AUTOSAR XML (schema 00046)
package /ComponentTypes
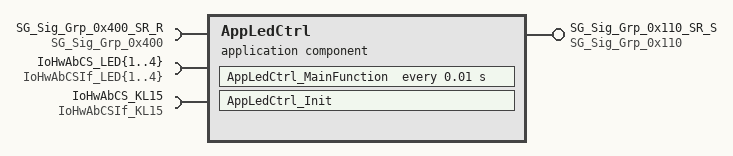
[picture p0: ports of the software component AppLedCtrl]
  application sw component type AppLedCtrl
    require port SG_Sig_Grp_0x400_SR_R: nonqueued-receiver-com-spec{data-element=SG_Sig_Grp_0x400, filter=data-filter-type=ALWAYS, init-value=fields=[CrcSig_Pack_0:0, CrcSig_Pack_1:0, CrcSig_Pack_2:0, Led1_Control:1, Led2_Control:1, Led3_Control:1, Led4_Control:1, SupB_Checksum_0x400:0, SupB_Counter_0x400:0]}, required-interface=SG_Sig_Grp_0x400
    provide port SG_Sig_Grp_0x110_SR_S: nonqueued-sender-com-spec{data-element=SG_Sig_Grp_0x110, init-value=fields=[Led1_State:0, Led2_State:0, Led3_State:0, Led4_State:0]}, provided-interface=SG_Sig_Grp_0x110
    5 x require port:
      IoHwAbCS_LED{1..4}: required-com-specs=[IoHwAbOp_LED{1..4}_Read, IoHwAbOp_LED{1..4}_Write], required-interface=IoHwAbCSIf_LED{1..4}
      IoHwAbCS_KL15: required-com-specs=[IoHwAbOp_KL15_Read], required-interface=IoHwAbCSIf_KL15
    behavior AppLedCtrl_InternalBehavior
      init event AppLedCtrl_InitEvent: start-on-event=AppLedCtrl_Init
      timing event TMT_Runnable: start-on-event=AppLedCtrl_MainFunction, period=0.01
      runnable AppLedCtrl_Init
      runnable AppLedCtrl_MainFunction
        data-receive-point-by-arguments:
          access REC_SG_Sig_Grp_0x400_SR_R_SG_Sig_Grp_0x400: accessed-variable=SG_Sig_Grp_0x400_SR_R.SG_Sig_Grp_0x400
        data-send-points:
          access SEND_SG_Sig_Grp_0x110_SR_S_SG_Sig_Grp_0x110: accessed-variable=SG_Sig_Grp_0x110_SR_S.SG_Sig_Grp_0x110
        9 x sync call:
          SC_IoHwAbCS_KL15_IoHwAbOp_KL15_Read: operation=IoHwAbCS_KL15.IoHwAbOp_KL15_Read
          SC_IoHwAbCS_LED1_IoHwAbOp_LED1_Read: operation=IoHwAbCS_LED1.IoHwAbOp_LED1_Read
          SC_IoHwAbCS_LED1_IoHwAbOp_LED1_Write: operation=IoHwAbCS_LED1.IoHwAbOp_LED1_Write
          SC_IoHwAbCS_LED2_IoHwAbOp_LED2_Read: operation=IoHwAbCS_LED2.IoHwAbOp_LED2_Read
          SC_IoHwAbCS_LED2_IoHwAbOp_LED2_Write: operation=IoHwAbCS_LED2.IoHwAbOp_LED2_Write
          SC_IoHwAbCS_LED3_IoHwAbOp_LED3_Read: operation=IoHwAbCS_LED3.IoHwAbOp_LED3_Read
          SC_IoHwAbCS_LED3_IoHwAbOp_LED3_Write: operation=IoHwAbCS_LED3.IoHwAbOp_LED3_Write
          SC_IoHwAbCS_LED4_IoHwAbOp_LED4_Read: operation=IoHwAbCS_LED4.IoHwAbOp_LED4_Read
          SC_IoHwAbCS_LED4_IoHwAbOp_LED4_Write: operation=IoHwAbCS_LED4.IoHwAbOp_LED4_Write
  swc implementation AppLedCtrl_Implementation: behavior=AppLedCtrl_InternalBehavior
